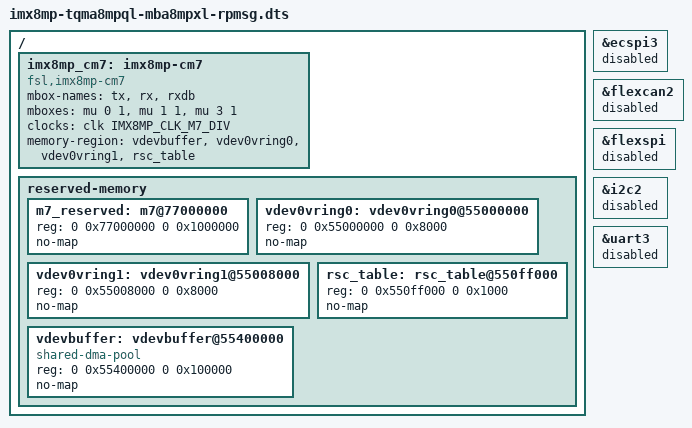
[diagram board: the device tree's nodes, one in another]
// SPDX-License-Identifier: (GPL-2.0-or-later OR MIT)
/*
 * Copyright 2021-2023 TQ-Systems GmbH <linux@ew.tq-group.com>,
 * D-82229 Seefeld, Germany.
 * Author: Alexander Stein
 */

#include "imx8mp-tqma8mpql-mba8mpxl.dts"

/ {
	imx8mp_cm7: imx8mp-cm7 {
		compatible = "fsl,imx8mp-cm7";
		mbox-names = "tx", "rx", "rxdb";
		mboxes = <&mu 0 1
			  &mu 1 1
			  &mu 3 1>;
		clocks = <&clk IMX8MP_CLK_M7_DIV>;
		memory-region = <&vdevbuffer>, <&vdev0vring0>,
				<&vdev0vring1>, <&rsc_table>;
	};

	reserved-memory {
		/*
		 * 0x7700_0000 ~ 0x77FF_FFFF is reserved for M7
		 * Must not be used from code running on Cortex-A cluster
		 * Must be in sync with linker settings for M7
		 */
		m7_reserved: m7@77000000 {
			reg = <0 0x77000000 0 0x1000000>;
			no-map;
		};

		vdev0vring0: vdev0vring0@55000000 {
			reg = <0 0x55000000 0 0x8000>;
			no-map;
		};

		vdev0vring1: vdev0vring1@55008000 {
			reg = <0 0x55008000 0 0x8000>;
			no-map;
		};

		/* Note: The underscore in node name is important! */
		rsc_table: rsc_table@550ff000 {
			reg = <0 0x550ff000 0 0x1000>;
			no-map;
		};

		vdevbuffer: vdevbuffer@55400000 {
			compatible = "shared-dma-pool";
			reg = <0 0x55400000 0 0x100000>;
			no-map;
		};
	};
};

/*
 * ATTENTION: M7 may use other IPs like SPI, CAN, GPIO, GPT, I2C, I2S, UART,
 * PWM, SDMA1/SDMA2. All IP used solely by M7 needs to be disabled to prevent
 * resource conflicts.
 * Keep in mind to configure the RDC according to the real product design to
 * enforce hardware based isolation.
 */

&ecspi3 {
	status = "disabled";
};

&flexcan2 {
	status = "disabled";
};

&flexspi {
	status = "disabled";
};

&i2c2 {
	status = "disabled";
};

&uart3 {
	status = "disabled";
};
